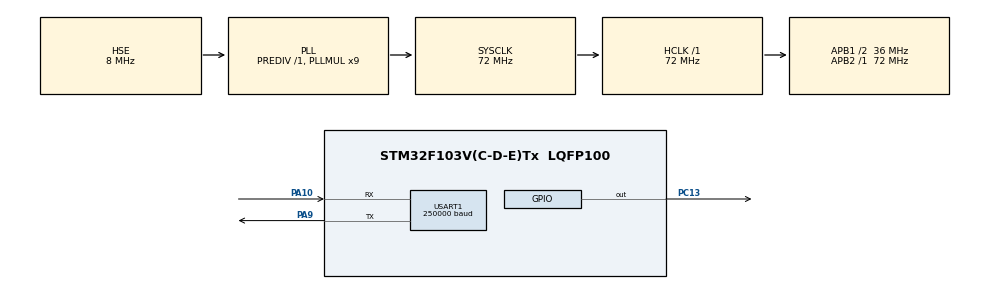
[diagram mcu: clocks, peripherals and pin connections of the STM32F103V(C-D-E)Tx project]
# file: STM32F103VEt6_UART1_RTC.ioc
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Dma.Request0=USART1_RX
Dma.Request1=USART1_TX
Dma.USART1_RX.0.Direction=DMA_PERIPH_TO_MEMORY
Dma.USART1_RX.0.Instance=DMA1_Channel5
Dma.USART1_RX.0.MemDataAlignment=DMA_MDATAALIGN_BYTE
Dma.USART1_RX.0.MemInc=DMA_MINC_ENABLE
Dma.USART1_RX.0.Mode=DMA_CIRCULAR
Dma.USART1_RX.0.PeriphDataAlignment=DMA_PDATAALIGN_BYTE
Dma.USART1_RX.0.PeriphInc=DMA_PINC_DISABLE
Dma.USART1_RX.0.Priority=DMA_PRIORITY_LOW
Dma.USART1_TX.1.Direction=DMA_MEMORY_TO_PERIPH
Dma.USART1_TX.1.Instance=DMA1_Channel4
Dma.USART1_TX.1.MemDataAlignment=DMA_MDATAALIGN_BYTE
Dma.USART1_TX.1.MemInc=DMA_MINC_ENABLE
Dma.USART1_TX.1.Mode=DMA_CIRCULAR
Dma.USART1_TX.1.PeriphDataAlignment=DMA_PDATAALIGN_BYTE
Dma.USART1_TX.1.PeriphInc=DMA_PINC_DISABLE
Dma.USART1_TX.1.Priority=DMA_PRIORITY_LOW
Mcu.Family=STM32F1
Mcu.Name=STM32F103V(C-D-E)Tx
Mcu.Package=LQFP100
NVIC.DMA1_Channel4_IRQn=true\:0\:0\:false\:false\:true
NVIC.DMA1_Channel5_IRQn=true\:0\:0\:false\:false\:true
NVIC.PriorityGroup=NVIC_PRIORITYGROUP_4
NVIC.USART1_IRQn=true\:0\:0\:false\:false\:true
OSC_IN.Mode=HSE-External-Oscillator
OSC_IN.Signal=RCC_OSC_IN
OSC_OUT.Mode=HSE-External-Oscillator
OSC_OUT.Signal=RCC_OSC_OUT
PA10.Mode=Asynchronous
PA10.Signal=USART1_RX
PA13.Mode=Serial_Wire
PA13.Signal=SYS_JTMS-SWDIO
PA14.Mode=Serial_Wire
PA14.Signal=SYS_JTCK-SWCLK
PA9.Mode=Asynchronous
PA9.Signal=USART1_TX
PC13-TAMPER-RTC.Signal=GPIO_Output
ProjectManager.HeapSize=0x200
ProjectManager.StackSize=0x400
ProjectManager.TargetToolchain=MDK-ARM V5
RCC.AHBFreq_Value=72000000
RCC.APB1CLKDivider=RCC_HCLK_DIV2
RCC.APB1Freq_Value=36000000
RCC.APB1TimFreq_Value=72000000
RCC.APB2Freq_Value=72000000
RCC.APB2TimFreq_Value=72000000
RCC.HCLKFreq_Value=72000000
RCC.HSIState=RCC_HSI_ON
RCC.PLLMUL=RCC_PLL_MUL9
RCC.PLLSourceVirtual=RCC_PLLSOURCE_HSE
RCC.SYSCLKFreq_VALUE=72000000
RCC.SYSCLKSource=RCC_SYSCLKSOURCE_PLLCLK
RCC.USBFreq_Value=72000000
RTC.Format=RTC_FORMAT_BIN
USART1.BaudRate=250000
VP_RTC_VS_RTC_Activate.Mode=RTC_Enabled
VP_RTC_VS_RTC_Calendar.Mode=RTC_Calendar
board=STM32F103VEt6_UART1_RTC

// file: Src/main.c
/**
  ******************************************************************************
  * File Name          : main.c
  * Description        : Main program body
  ******************************************************************************
  *
  * COPYRIGHT(c) 2016 STMicroelectronics
  *
  * Redistribution and use in source and binary forms, with or without modification,
  * are permitted provided that the following conditions are met:
  *   1. Redistributions of source code must retain the above copyright notice,
  *      this list of conditions and the following disclaimer.
  *   2. Redistributions in binary form must reproduce the above copyright notice,
  *      this list of conditions and the following disclaimer in the documentation
  *      and/or other materials provided with the distribution.
  *   3. Neither the name of STMicroelectronics nor the names of its contributors
  *      may be used to endorse or promote products derived from this software
  *      without specific prior written permission.
  *
  * THIS SOFTWARE IS PROVIDED BY THE COPYRIGHT HOLDERS AND CONTRIBUTORS "AS IS"
  * AND ANY EXPRESS OR IMPLIED WARRANTIES, INCLUDING, BUT NOT LIMITED TO, THE
  * IMPLIED WARRANTIES OF MERCHANTABILITY AND FITNESS FOR A PARTICULAR PURPOSE ARE
  * DISCLAIMED. IN NO EVENT SHALL THE COPYRIGHT HOLDER OR CONTRIBUTORS BE LIABLE
  * FOR ANY DIRECT, INDIRECT, INCIDENTAL, SPECIAL, EXEMPLARY, OR CONSEQUENTIAL
  * DAMAGES (INCLUDING, BUT NOT LIMITED TO, PROCUREMENT OF SUBSTITUTE GOODS OR
  * SERVICES; LOSS OF USE, DATA, OR PROFITS; OR BUSINESS INTERRUPTION) HOWEVER
  * CAUSED AND ON ANY THEORY OF LIABILITY, WHETHER IN CONTRACT, STRICT LIABILITY,
  * OR TORT (INCLUDING NEGLIGENCE OR OTHERWISE) ARISING IN ANY WAY OUT OF THE USE
  * OF THIS SOFTWARE, EVEN IF ADVISED OF THE POSSIBILITY OF SUCH DAMAGE.
  *
  ******************************************************************************
  */
#include "main.h"
#include "stm32f1xx_hal.h"

/* USER CODE BEGIN Includes */
#include "string.h"
#include "stdio.h"
/* USER CODE END Includes */

RTC_HandleTypeDef hrtc;

UART_HandleTypeDef huart1;
DMA_HandleTypeDef hdma_usart1_rx;
DMA_HandleTypeDef hdma_usart1_tx;

/* USER CODE BEGIN PV */
/* Private variables ---------------------------------------------------------*/
#ifdef __GNUC__
  #define PUTCHAR_PROTOTYPE int __io_putchar(int ch)
#else
  #define PUTCHAR_PROTOTYPE int fputc(int ch, FILE *f)
#endif
PUTCHAR_PROTOTYPE
{
	HAL_UART_Transmit(&huart1, (uint8_t *)&ch, 1, 100);
	return ch;
}
/* USER CODE END PV */

void SystemClock_Config(void);
void Error_Handler(void);
static void MX_GPIO_Init(void);
static void MX_DMA_Init(void);
static void MX_USART1_UART_Init(void);
static void MX_RTC_Init(void);

/* USER CODE BEGIN PFP */
/* Private function prototypes -----------------------------------------------*/

/* USER CODE END PFP */

/* USER CODE BEGIN 0 */
uint8_t RX_Data[64], RX_Buffer[64], RX_Index=0, mystring[]="Electronic4U \r";
uint8_t Second, Minute, Hour;
uint8_t Date, Day, Month, Year;
RTC_TimeTypeDef sTime;
RTC_DateTypeDef DateToUpdate;
/* USER CODE END 0 */

int main(void)
{

  /* MCU Configuration----------------------------------------------------------*/

  /* Reset of all peripherals, Initializes the Flash interface and the Systick. */
  HAL_Init();

  /* Configure the system clock */
  SystemClock_Config();

  /* Initialize all configured peripherals */
  MX_GPIO_Init();
  MX_DMA_Init();
  MX_USART1_UART_Init();
  MX_RTC_Init();

  /* USER CODE BEGIN 2 */
		HAL_UART_Receive_IT(&huart1, (uint8_t *)RX_Buffer, 1);

  /* USER CODE END 2 */

  /* Infinite loop */
  while (1)
  {

  /* USER CODE BEGIN 3 */
		//HAL_UART_Transmit(&huart1, (uint8_t *)mystring, strlen(( const char *)mystring), 100);
		HAL_RTC_GetTime(&hrtc,&sTime,RTC_FORMAT_BIN);
		HAL_RTC_GetDate(&hrtc,&DateToUpdate,RTC_FORMAT_BIN);
		Second = sTime.Seconds;
		Minute = sTime.Minutes;
		Hour = sTime.Hours;
		Day = DateToUpdate.Date;
		Date = DateToUpdate.WeekDay;
		Month = DateToUpdate.Month;
		Year = DateToUpdate.Year;

		printf("Second:%d  -\n", Second);
		printf("Minute:%d  -\n", Minute);
		printf("Hour:%d  -\n", Hour);

		printf ("Day:%d  -\n", Day);
		printf ("Date:%d  -\n", Date);
		printf ("Month:%d  -\n", Month);
		printf ("Year:%d  -\n", Year);

		//sprintf((char *)Sen_Data,"%s",Receive_Data);
		HAL_UART_Transmit(&huart1, (uint8_t *)RX_Data, strlen((const char *)RX_Data), 100);
		HAL_GPIO_TogglePin(GPIOC, GPIO_PIN_13);
		HAL_Delay(1000);
  }
  /* USER CODE END 3 */
}

/** System Clock Configuration
*/
void SystemClock_Config(void)
{

  RCC_OscInitTypeDef RCC_OscInitStruct;
  RCC_ClkInitTypeDef RCC_ClkInitStruct;
  RCC_PeriphCLKInitTypeDef PeriphClkInit;

    /**Initializes the CPU, AHB and APB busses clocks
    */
  RCC_OscInitStruct.OscillatorType = RCC_OSCILLATORTYPE_LSI|RCC_OSCILLATORTYPE_HSE;
  RCC_OscInitStruct.HSEState = RCC_HSE_ON;
  RCC_OscInitStruct.HSEPredivValue = RCC_HSE_PREDIV_DIV1;
  RCC_OscInitStruct.HSIState = RCC_HSI_ON;
  RCC_OscInitStruct.LSIState = RCC_LSI_ON;
  RCC_OscInitStruct.PLL.PLLState = RCC_PLL_ON;
  RCC_OscInitStruct.PLL.PLLSource = RCC_PLLSOURCE_HSE;
  RCC_OscInitStruct.PLL.PLLMUL = RCC_PLL_MUL9;
  if (HAL_RCC_OscConfig(&RCC_OscInitStruct) != HAL_OK)
  {
    Error_Handler();
  }

    /**Initializes the CPU, AHB and APB busses clocks
    */
  RCC_ClkInitStruct.ClockType = RCC_CLOCKTYPE_HCLK|RCC_CLOCKTYPE_SYSCLK
                              |RCC_CLOCKTYPE_PCLK1|RCC_CLOCKTYPE_PCLK2;
  RCC_ClkInitStruct.SYSCLKSource = RCC_SYSCLKSOURCE_PLLCLK;
  RCC_ClkInitStruct.AHBCLKDivider = RCC_SYSCLK_DIV1;
  RCC_ClkInitStruct.APB1CLKDivider = RCC_HCLK_DIV2;
  RCC_ClkInitStruct.APB2CLKDivider = RCC_HCLK_DIV1;

  if (HAL_RCC_ClockConfig(&RCC_ClkInitStruct, FLASH_LATENCY_2) != HAL_OK)
  {
    Error_Handler();
  }

  PeriphClkInit.PeriphClockSelection = RCC_PERIPHCLK_RTC;
  PeriphClkInit.RTCClockSelection = RCC_RTCCLKSOURCE_LSI;
  if (HAL_RCCEx_PeriphCLKConfig(&PeriphClkInit) != HAL_OK)
  {
    Error_Handler();
  }

    /**Configure the Systick interrupt time
    */
  HAL_SYSTICK_Config(HAL_RCC_GetHCLKFreq()/1000);

    /**Configure the Systick
    */
  HAL_SYSTICK_CLKSourceConfig(SYSTICK_CLKSOURCE_HCLK);

  /* SysTick_IRQn interrupt configuration */
  HAL_NVIC_SetPriority(SysTick_IRQn, 0, 0);
}

/* RTC init function */
static void MX_RTC_Init(void)
{

  RTC_TimeTypeDef sTime;
  RTC_DateTypeDef DateToUpdate;

    /**Initialize RTC Only
    */
  hrtc.Instance = RTC;
  hrtc.Init.AsynchPrediv = RTC_AUTO_1_SECOND;
  hrtc.Init.OutPut = RTC_OUTPUTSOURCE_ALARM;
  if (HAL_RTC_Init(&hrtc) != HAL_OK)
  {
    Error_Handler();
  }

    /**Initialize RTC and set the Time and Date
    */
  sTime.Hours = 1;
  sTime.Minutes = 0;
  sTime.Seconds = 0;

  if (HAL_RTC_SetTime(&hrtc, &sTime, RTC_FORMAT_BIN) != HAL_OK)
  {
    Error_Handler();
  }

  DateToUpdate.WeekDay = RTC_WEEKDAY_MONDAY;
  DateToUpdate.Month = RTC_MONTH_JANUARY;
  DateToUpdate.Date = 1;
  DateToUpdate.Year = 0;

  if (HAL_RTC_SetDate(&hrtc, &DateToUpdate, RTC_FORMAT_BIN) != HAL_OK)
  {
    Error_Handler();
  }

}

/* USART1 init function */
static void MX_USART1_UART_Init(void)
{

  huart1.Instance = USART1;
  huart1.Init.BaudRate = 250000;
  huart1.Init.WordLength = UART_WORDLENGTH_8B;
  huart1.Init.StopBits = UART_STOPBITS_1;
  huart1.Init.Parity = UART_PARITY_NONE;
  huart1.Init.Mode = UART_MODE_TX_RX;
  huart1.Init.HwFlowCtl = UART_HWCONTROL_NONE;
  huart1.Init.OverSampling = UART_OVERSAMPLING_16;
  if (HAL_UART_Init(&huart1) != HAL_OK)
  {
    Error_Handler();
  }

}

static void MX_DMA_Init(void)
{
  /* DMA controller clock enable */
  __HAL_RCC_DMA1_CLK_ENABLE();

  /* DMA interrupt init */
  /* DMA1_Channel4_IRQn interrupt configuration */
  HAL_NVIC_SetPriority(DMA1_Channel4_IRQn, 0, 0);
  HAL_NVIC_EnableIRQ(DMA1_Channel4_IRQn);
  /* DMA1_Channel5_IRQn interrupt configuration */
  HAL_NVIC_SetPriority(DMA1_Channel5_IRQn, 0, 0);
  HAL_NVIC_EnableIRQ(DMA1_Channel5_IRQn);

}

/** Configure pins as
        * Analog
        * Input
        * Output
        * EVENT_OUT
        * EXTI
*/
static void MX_GPIO_Init(void)
{

  GPIO_InitTypeDef GPIO_InitStruct;

  /* GPIO Ports Clock Enable */
  __HAL_RCC_GPIOC_CLK_ENABLE();
  __HAL_RCC_GPIOA_CLK_ENABLE();

  /*Configure GPIO pin Output Level */
  HAL_GPIO_WritePin(GPIOC, GPIO_PIN_13, GPIO_PIN_RESET);

  /*Configure GPIO pin : PC13 */
  GPIO_InitStruct.Pin = GPIO_PIN_13;
  GPIO_InitStruct.Mode = GPIO_MODE_OUTPUT_PP;
  GPIO_InitStruct.Speed = GPIO_SPEED_FREQ_LOW;
  HAL_GPIO_Init(GPIOC, &GPIO_InitStruct);

}

/* USER CODE BEGIN 4 */
void HAL_UART_RxCpltCallback(UART_HandleTypeDef *huart)
{
	if(huart->Instance == huart1.Instance)
	{
		if (RX_Buffer[0] != 10)
			{
				RX_Data[RX_Index++] = RX_Buffer[0];
			}
		if (RX_Buffer[0] == 10)
			{
				RX_Index=0;
			}
	HAL_UART_Receive_IT(&huart1, (uint8_t *)RX_Buffer, 1);
	}
}

/* USER CODE END 4 */

void Error_Handler(void)
{
  while(1)
  {
  }
}

/************************ (C) COPYRIGHT STMicroelectronics *****END OF FILE****/
